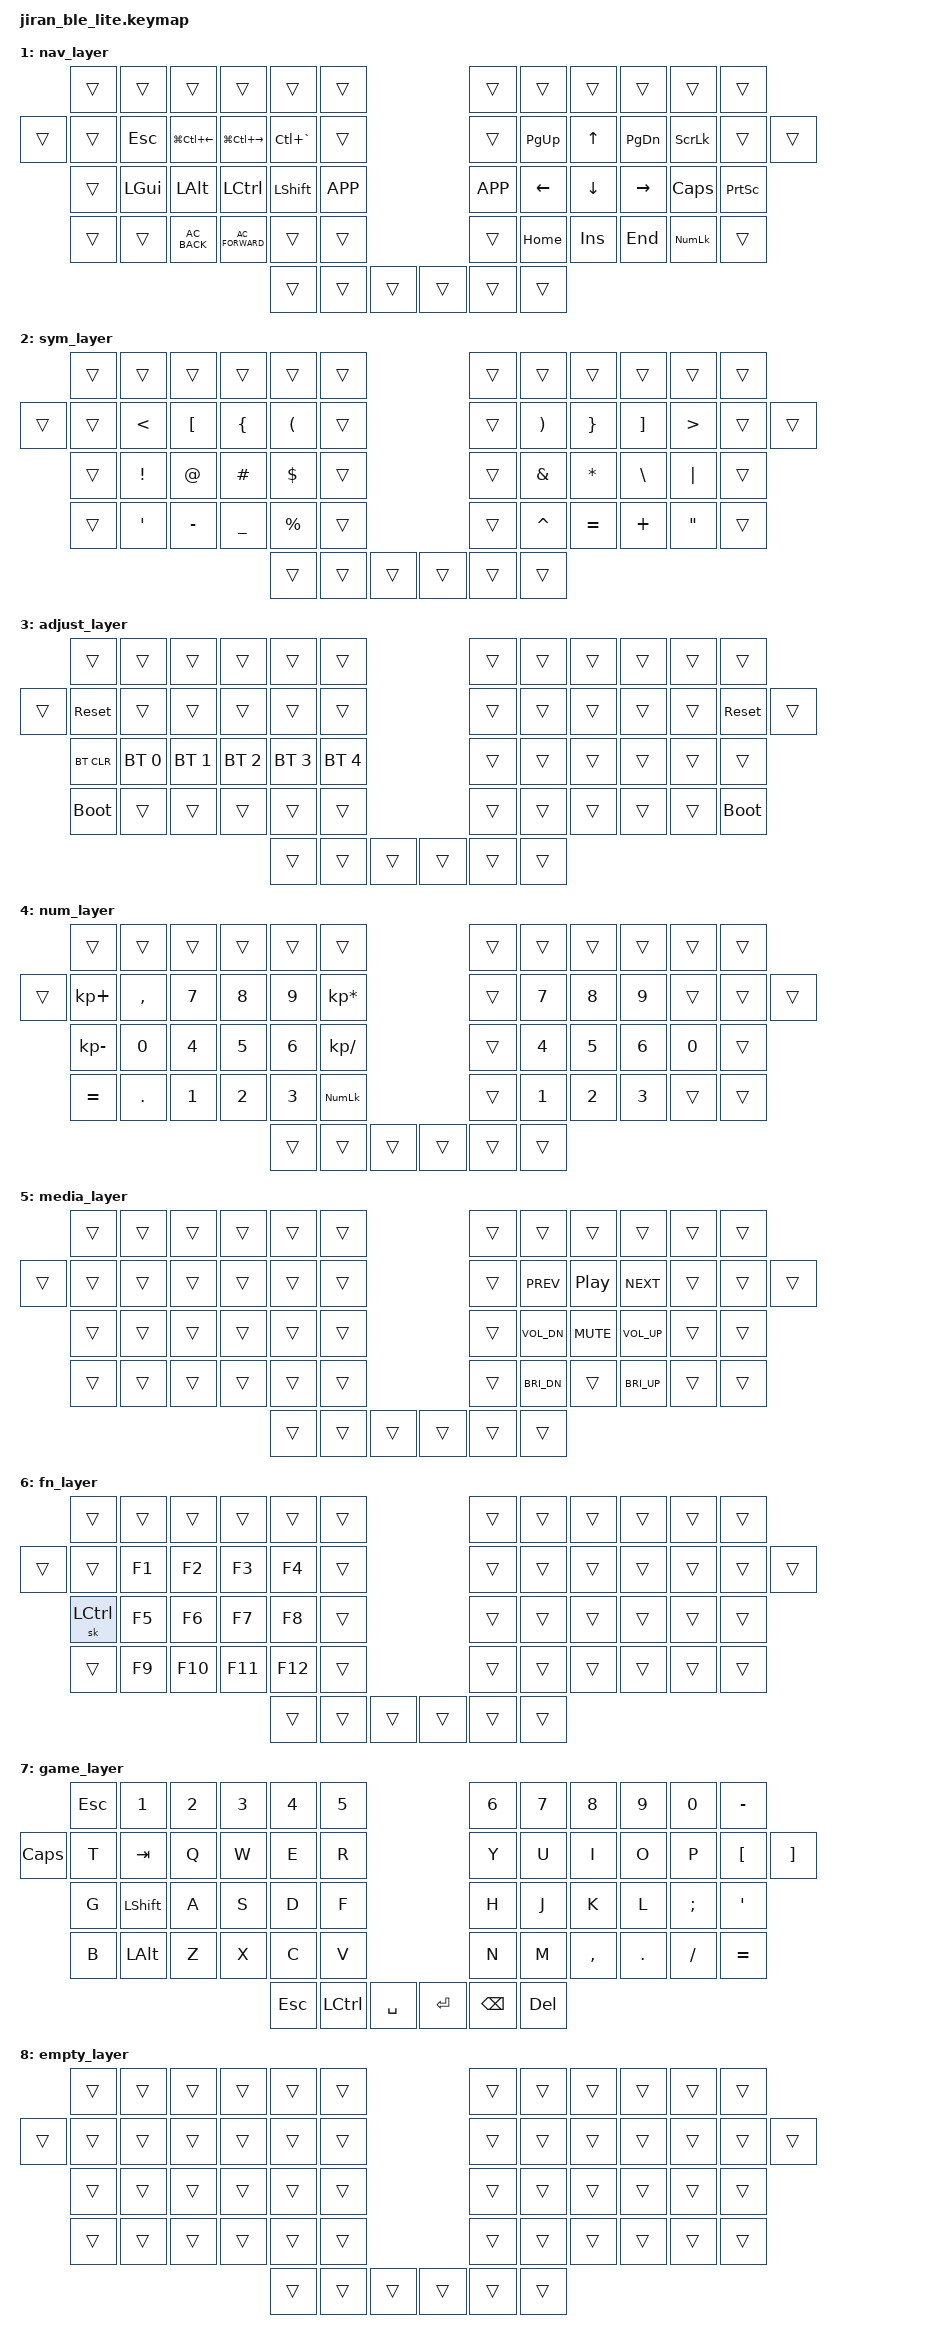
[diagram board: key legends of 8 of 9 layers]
// Copyright (c) 2021 The ZMK Contributors
// SPDX-License-Identifier: MIT

// https://zmk.dev/docs/config/system
// https://zmk.dev/docs/behaviors/outputs

#include <behaviors.dtsi>
#include <dt-bindings/zmk/keys.h>
#include <dt-bindings/zmk/bt.h>

#define HRML(k1,k2,k3,k4) &ht LGUI k1   &ht LALT k2   &ht LCTRL k3  &ht LSHFT k4
#define HRMR(k1,k2,k3,k4) &ht RSHFT k1  &ht RCTRL k2  &ht RALT k3   &ht RGUI k4
#define TERM &kp LC(GRAVE)
#define TSK_V &kp LG(TAB)
#define DES_P &kp LG(LC(LEFT))
#define DES_N &kp LG(LC(RIGHT))

#define DEFAULT  0
#define NAV      1
#define SYM      2
#define ADJ      3
#define NUM      4
#define MEDIA    5
#define FN       6
#define GAME     7

#define COMBO(NAME, BINDINGS, KEYPOS, LAYERS) \
    combo_##NAME { \
        timeout-ms = <50>; \
        bindings = <BINDINGS>; \
        key-positions = <KEYPOS>; \
        layers = <LAYERS>; \
    };

/ {
    behaviors {
        ht: hold_tap {
            compatible = "zmk,behavior-hold-tap";
            label = "HOMEROW_MODS";
            #binding-cells = <2>;
            tapping_term_ms = <150>;
            quick_tap_ms = <250>;
            flavor = "tap-preferred";
            bindings = <&kp>, <&kp>;
        };
        tt: layer_tap {
            compatible = "zmk,behavior-hold-tap";
            label = "THUMBROW_TAPS";
            #binding-cells = <2>;
            tapping_term_ms = <150>;
            quick_tap_ms = <250>;
            flavor = "tap-preferred";
            bindings = <&mo>, <&kp>;
        };
    };

    conditional_layers {
        compatible = "zmk,conditional-layers";
        adjust_layer {
            if-layers = <NAV SYM>;
            then-layer = <ADJ>;
        };
    };

    combos {
        compatible = "zmk,combos";
        COMBO(delete,       &kp DEL,       27 28,    DEFAULT)
        COMBO(backspace,    &kp BSPC,      28 29,    DEFAULT)
        COMBO(enter,        &kp RET,       29 30,    DEFAULT)
        COMBO(game,         &tog GAME,      0 52,    DEFAULT GAME)
        COMBO(tasks,        TSK_V,         15 16,    NAV)
        COMBO(goup,         &kp LA(UP),    40 41,    NAV)
    };

//         ╭───────┬───────┬───────┬───────┬───────┬───────╮                    ╭───────┬───────┬───────┬───────┬───────┬───────╮
//         |   0   |   1   |   2   |   3   |   4   |   5   |                    |   6   |   7   |   8   |   9   |  10   |  11   |
// ╭───────┤   13  |   14  |   15  |   16  |   17  |   18  |                    |   19  |   20  |   21  |   22  |  23   |  24   ├───────╮
// |   12  |   26  |   27  |   28  |   29  |   30  |   31  |                    |   32  |   33  |   34  |   35  |  36   |  37   |  25   |
// ╰───────┤   38  |   39  |   40  |   41  |   42  |   43  |                    |   44  |   45  |   46  |   47  |  48   |  49   ├───────╯
//         ╰───────┴───────┴───────────────┼───────┼───────┼───────╮    ╭───────┼───────┼───────┼───────────────────────────────╯
//                                         |   50  |   51  |   52  |    |   53  |   54  |   55  |
//                                         ╰───────┴───────┴───────╯    ╰───────┴───────┴───────╯

    keymap {
        compatible = "zmk,keymap";

        default_layer {
//         ╭───────┬───────┬───────┬───────┬───────┬───────╮                    ╭───────┬───────┬───────┬───────┬───────┬───────╮
//         |  ESC  |   1   |   2   |   3   |   4   |   5   |                    |   6   |   7   |   8   |   9   |   0   |   -   |
// ╭───────┤   [   |   Q   |   W   |   E   |   R   |   T   |                    |   Y   |   U   |   I   |   O   |   P   |   ]   ├───────╮
// |       |   `   |   A   |   S   |   D   |   F   |   G   |                    |   H   |   J   |   K   |   L   |   ;   |   '   |       |
// ╰───────┤   -   |   Z   |   X   |   C   |   V   |   B   |                    |   N   |   M   |   ,   |   .   |   /   |   =   ├───────╯
//         ╰───────┴───────┴───────────────┼───────┼───────┼───────╮    ╭───────┼───────┼───────┼───────────────────────────────╯
//                                         |  ESC  |  TAB  |  SPC  |    |  ENT  |  BKSP |  DEL  |
//                                         ╰───────┴───────┴───────╯    ╰───────┴───────┴───────╯
            bindings = <
        &kp ESC    &kp N1      &kp N2  &kp N3      &kp N4       &kp N5                                      &kp N6          &kp N7      &kp N8     &kp N9   &kp N0    &kp MINUS
&trans  &kp LBKT   &kp Q       &kp W   &kp E       &kp R        &kp T                                       &kp Y           &kp U       &kp I      &kp O    &kp P     &kp RBKT   &trans
        &kp GRAVE  HRML(A,     S,      D,          F)           &kp G                                       &kp H           HRMR(J,     K,         L,       SEMI)     &kp SQT
        &kp MINUS  &kp Z       &kp X   &kp C       &kp V        &kp B                                       &kp N           &kp M       &kp COMMA  &kp DOT  &kp FSLH  &kp EQUAL
                                                   &tt FN ESC   &tt NUM TAB  &tt NAV SPACE     &tt SYM RET  &tt MEDIA BSPC  &tt FN DEL
            >;
        };

        nav_layer {
//         ╭───────┬───────┬───────┬───────┬───────┬───────╮                    ╭───────┬───────┬───────┬───────┬───────┬───────╮
//         |       |       |       |       |       |       |                    |       |       |       |       |       |       |
// ╭───────┤       |  ESC  | <DESK | DESK> | TRMNL |       |                    |       | PG UP |  UP   | PG DN | SLCK  |       ├───────╮
// |       |       |  GUI  |  ALT  | CTRL  | SHIFT |  APP  |                    |  APP  | LEFT  | DOWN  | RIGHT | CLCK  | PRN S |       |
// ╰───────┤       |       |  BCK  |  FWD  |       |       |                    |       | HOME  |  INS  |  END  | NLCK  |       ├───────╯
//         ╰───────┴───────┴───────────────┼───────┼───────┼───────╮    ╭───────┼───────┼───────┼───────────────────────────────╯
//                                         |       |       |       |    |       |       |       |
//                                         ╰───────┴───────┴───────╯    ╰───────┴───────┴───────╯
            bindings = <
        &trans   &trans    &trans         &trans            &trans         &trans                       &trans     &trans     &trans    &trans     &trans       &trans
&trans  &trans   &kp ESC   DES_P          DES_N             TERM           &trans                       &trans     &kp PG_UP  &kp UP    &kp PG_DN  &kp SLCK     &trans     &trans
        &trans   &kp LGUI  &kp LALT       &kp LCTRL         &kp LSHFT      &kp K_APP                    &kp K_APP  &kp LEFT   &kp DOWN  &kp RIGHT  &kp CLCK     &kp PSCRN
        &trans   &trans    &kp C_AC_BACK  &kp C_AC_FORWARD  &trans         &trans                       &trans     &kp HOME   &kp INS   &kp END    &kp KP_NLCK  &trans
                                                            &trans         &trans     &trans    &trans  &trans     &trans
            >;
        };

        sym_layer {
//         ╭───────┬───────┬───────┬───────┬───────┬───────╮                    ╭───────┬───────┬───────┬───────┬───────┬───────╮
//         |       |       |       |       |       |       |                    |       |       |       |       |       |       |
// ╭───────┤       |   <   |   [   |   {   |   (   |       |                    |       |   )   |   }   |   ]   |   >   |       ├───────╮
// |       |       |   !   |   @   |   #   |   $   |       |                    |       |   &   |   *   |   \   |   |   |       |       |
// ╰───────┤       |   '   |   -   |   _   |   %   |       |                    |       |   ^   |   =   |   +   |   "   |       ├───────╯
//         ╰───────┴───────┴───────────────┼───────┼───────┼───────╮    ╭───────┼───────┼───────┼───────────────────────────────╯
//                                         |       |       |       |    |       |       |       |
//                                         ╰───────┴───────┴───────╯    ╰───────┴───────┴───────╯
            bindings = <
        &trans  &trans    &trans     &trans     &trans     &trans                    &trans  &trans     &trans     &trans    &trans    &trans
&trans  &trans  &kp LT    &kp LBKT   &kp LBRC   &kp LPAR   &trans                    &trans  &kp RPAR   &kp RBRC   &kp RBKT  &kp GT    &trans &trans
        &trans  &kp EXCL  &kp AT     &kp HASH   &kp DLLR   &trans                    &trans  &kp AMPS   &kp ASTRK  &kp BSLH  &kp PIPE  &trans
        &trans  &kp SQT   &kp MINUS  &kp UNDER  &kp PRCNT  &trans                    &trans  &kp CARET  &kp EQUAL  &kp PLUS  &kp DQT   &trans
                                                &trans     &trans  &trans    &trans  &trans  &trans
            >;
        };

        adjust_layer {
//         ╭───────┬───────┬───────┬───────┬───────┬───────╮                    ╭───────┬───────┬───────┬───────┬───────┬───────╮
//         |       |       |       |       |       |       |                    |       |       |       |       |       |       |
// ╭───────┤ RESET |       |       |       |       |       |                    |       |       |       |       |       | RESET ├───────╮
// |       | BTCLR |  BT0  |  BT1  |  BT2  |  BT3  |  BT4  |                    |       |       |       |       |       |       |       |
// ╰───────┤ BOOTL |       |       |       |       |       |                    |       |       |       |       |       | BOOTL ├───────╯
//         ╰───────┴───────┴───────────────┼───────┼───────┼───────╮    ╭───────┼───────┼───────┼───────────────────────────────╯
//                                         |       |       |       |    |       |       |       |
//                                         ╰───────┴───────┴───────╯    ╰───────┴───────┴───────╯
            bindings = <
        &trans       &trans        &trans        &trans        &trans        &trans                    &trans  &trans  &trans  &trans  &trans  &trans
&trans  &sys_reset   &trans        &trans        &trans        &trans        &trans                    &trans  &trans  &trans  &trans  &trans  &sys_reset   &trans
        &bt BT_CLR   &bt BT_SEL 0  &bt BT_SEL 1  &bt BT_SEL 2  &bt BT_SEL 3  &bt BT_SEL 4              &trans  &trans  &trans  &trans  &trans  &trans
        &bootloader  &trans        &trans        &trans        &trans        &trans                    &trans  &trans  &trans  &trans  &trans  &bootloader
                                                               &trans        &trans  &trans    &trans  &trans  &trans
            >;
        };

        num_layer {
//         ╭───────┬───────┬───────┬───────┬───────┬───────╮                    ╭───────┬───────┬───────┬───────┬───────┬───────╮
//         |       |       |       |       |       |       |                    |       |       |       |       |       |       |
// ╭───────┤   +   |   ,   |   7   |   8   |   9   |   *   |                    |       |   7   |   8   |   9   |       |       ├───────╮
// |       |   -   |   0   |   4   |   5   |   6   |   /   |                    |       |   4   |   5   |   6   |   0   |       |       |
// ╰───────┤   =   |   .   |   1   |   2   |   3   | NLCK  |                    |       |   1   |   2   |   3   |       |       ├───────╯
//         ╰───────┴───────┴───────────────┼───────┼───────┼───────╮    ╭───────┼───────┼───────┼───────────────────────────────╯
//                                         |       |       |       |    |       |       |       |
//                                         ╰───────┴───────┴───────╯    ╰───────┴───────┴───────╯
            bindings = <
        &trans        &trans     &trans  &trans  &trans  &trans                             &trans  &trans  &trans  &trans  &trans     &trans
&trans  &kp KP_PLUS   &kp COMMA  &kp N7  &kp N8  &kp N9  &kp KP_MULTIPLY                    &trans  &kp N7  &kp N8  &kp N9  &trans     &trans  &trans
        &kp KP_MINUS  &kp N0     &kp N4  &kp N5  &kp N6  &kp KP_DIVIDE                      &trans  &kp N4  &kp N5  &kp N6  &kp N0     &trans
        &kp EQUAL     &kp DOT    &kp N1  &kp N2  &kp N3  &kp KP_NLCK                        &trans  &kp N1  &kp N2  &kp N3  &trans     &trans
                                                 &trans  &trans             &trans  &trans  &trans  &trans
            >;
        };

        media_layer {
//         ╭───────┬───────┬───────┬───────┬───────┬───────╮                    ╭───────┬───────┬───────┬───────┬───────┬───────╮
//         |       |       |       |       |       |       |                    |       |       |       |       |       |       |
// ╭───────┤       |       |       |       |       |       |                    |       |  <<   |  P\P  |  >>   |       |       ├───────╮
// |       |       |       |       |       |       |       |                    |       | VOL-  | MUTE  | VOL+  |       |       |       |
// ╰───────┤       |       |       |       |       |       |                    |       | BRI-  |       | BRI+  |       |       ├───────╯
//         ╰───────┴───────┴───────────────┼───────┼───────┼───────╮    ╭───────┼───────┼───────┼───────────────────────────────╯
//                                         |       |       |       |    |       |       |       |
//                                         ╰───────┴───────┴───────╯    ╰───────┴───────┴───────╯
            bindings = <
        &trans  &trans  &trans  &trans  &trans  &trans                    &trans  &trans        &trans      &trans        &trans  &trans
&trans  &trans  &trans  &trans  &trans  &trans  &trans                    &trans  &kp C_PREV    &kp C_PP    &kp C_NEXT    &trans  &trans  &trans
        &trans  &trans  &trans  &trans  &trans  &trans                    &trans  &kp C_VOL_DN  &kp C_MUTE  &kp C_VOL_UP  &trans  &trans
        &trans  &trans  &trans  &trans  &trans  &trans                    &trans  &kp C_BRI_DN  &trans      &kp C_BRI_UP  &trans  &trans
                                        &trans  &trans  &trans    &trans  &trans  &trans
            >;
        };

        fn_layer {
//         ╭───────┬───────┬───────┬───────┬───────┬───────╮                    ╭───────┬───────┬───────┬───────┬───────┬───────╮
//         |       |       |       |       |       |       |                    |       |       |       |       |       |       |
// ╭───────┤       |  F1   |  F2   |  F3   |  F4   |       |                    |       |       |       |       |       |       ├───────╮
// |       | SCTRL |  F5   |  F6   |  F7   |  F8   |       |                    |       |       |       |       |       |       |       |
// ╰───────┤       |  F9   |  F10  |  F11  |  F12  |       |                    |       |       |       |       |       |       ├───────╯
//         ╰───────┴───────┴───────────────┼───────┼───────┼───────╮    ╭───────┼───────┼───────┼───────────────────────────────╯
//                                         |       |       |       |    |       |       |       |
//                                         ╰───────┴───────┴───────╯    ╰───────┴───────┴───────╯
            bindings = <
        &trans     &trans  &trans   &trans   &trans   &trans                    &trans  &trans  &trans  &trans  &trans  &trans
&trans  &trans     &kp F1  &kp F2   &kp F3   &kp F4   &trans                    &trans  &trans  &trans  &trans  &trans  &trans  &trans
        &sk LCTRL  &kp F5  &kp F6   &kp F7   &kp F8   &trans                    &trans  &trans  &trans  &trans  &trans  &trans
        &trans     &kp F9  &kp F10  &kp F11  &kp F12  &trans                    &trans  &trans  &trans  &trans  &trans  &trans
                                             &trans   &trans  &trans    &trans  &trans  &trans
            >;
        };

        game_layer {
//         ╭───────┬───────┬───────┬───────┬───────┬───────╮                    ╭───────┬───────┬───────┬───────┬───────┬───────╮
//         |  ESC  |   1   |   2   |   3   |   4   |   5   |                    |   6   |   7   |   8   |   9   |   0   |   -   |
// ╭───────┤   T   |  TAB  |   Q   |   W   |   E   |   R   |                    |   Y   |   U   |   I   |   O   |   P   |   [   ├───────╮
// | CAPS  |   G   | SHIFT |   A   |   S   |   D   |   F   |                    |   H   |   J   |   K   |   L   |   ;   |   '   |   ]   |
// ╰───────┤   B   |  ALT  |   Z   |   X   |   C   |   V   |                    |   N   |   M   |   ,   |   .   |   /   |   =   ├───────╯
//         ╰───────┴───────┴───────────────┼───────┼───────┼───────╮    ╭───────┼───────┼───────┼───────────────────────────────╯
//                                         |  ESC  | CTRL  | SPACE |    |  ENT  | BKSP  |  DEL  |
//                                         ╰───────┴───────┴───────╯    ╰───────┴───────┴───────╯
            bindings = <
          &kp ESC  &kp N1     &kp N2  &kp N3   &kp N4  &kp N5                           &kp N6    &kp N7  &kp N8     &kp N9   &kp N0    &kp MINUS
&kp CLCK  &kp T    &kp TAB    &kp Q   &kp W    &kp E   &kp R                            &kp Y     &kp U   &kp I      &kp O    &kp P     &kp LBKT   &kp RBKT
          &kp G    &kp LSHFT  &kp A   &kp S    &kp D   &kp F                            &kp H     &kp J   &kp K      &kp L    &kp SEMI  &kp SQT
          &kp B    &kp LALT   &kp Z   &kp X    &kp C   &kp V                            &kp N     &kp M   &kp COMMA  &kp DOT  &kp FSLH  &kp EQUAL
                                              &kp ESC  &kp LCTRL  &kp SPACE    &kp RET  &kp BSPC  &kp DEL
            >;
        };

        empty_layer {
//         ╭───────┬───────┬───────┬───────┬───────┬───────╮                    ╭───────┬───────┬───────┬───────┬───────┬───────╮
//         |       |       |       |       |       |       |                    |       |       |       |       |       |       |
// ╭───────┤       |       |       |       |       |       |                    |       |       |       |       |       |       ├───────╮
// |       |       |       |       |       |       |       |                    |       |       |       |       |       |       |       |
// ╰───────┤       |       |       |       |       |       |                    |       |       |       |       |       |       ├───────╯
//         ╰───────┴───────┴───────────────┼───────┼───────┼───────╮    ╭───────┼───────┼───────┼───────────────────────────────╯
//                                         |       |       |       |    |       |       |       |
//                                         ╰───────┴───────┴───────╯    ╰───────┴───────┴───────╯
            bindings = <
        &trans  &trans  &trans  &trans  &trans  &trans                    &trans  &trans  &trans  &trans  &trans  &trans
&trans  &trans  &trans  &trans  &trans  &trans  &trans                    &trans  &trans  &trans  &trans  &trans  &trans  &trans
        &trans  &trans  &trans  &trans  &trans  &trans                    &trans  &trans  &trans  &trans  &trans  &trans
        &trans  &trans  &trans  &trans  &trans  &trans                    &trans  &trans  &trans  &trans  &trans  &trans
                                        &trans  &trans  &trans    &trans  &trans  &trans
            >;
        };

    };
};
